# ATSAMRH71F20B register map
Vendor: Microchip Technology; Series: SAMRH71; File version: 0
CPU: CM7 r1p1, little endian, MPU, FPU, 3 interrupt priority bits
Registers are 32-bit, read-write, reset 0x0 unless marked. A register's access mark holds for its fields unless they carry their own. Offsets are from the block's base; [hi:lo] are bit positions; 'fields as' and 'values as' point back to an identical list.

## SUPC — Supply Controller
Base 0x40100210; register names take the prefix SUPC_
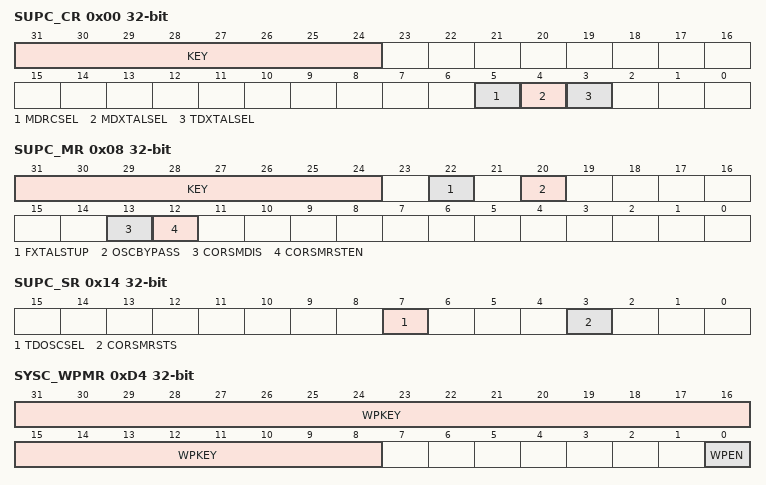
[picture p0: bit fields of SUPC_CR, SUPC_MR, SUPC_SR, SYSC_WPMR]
0x00 SUPC_CR wo — Supply Controller Control Register
  [31:24] KEY — Password
    165=PASSWD (Writing any other value in this field aborts the write operation.)
  [5] MDRCSEL — Monitoring Domain RC Oscillator Select
    0=NO_EFFECT; 1=CRYSTAL_SEL (If KEY is correct, XTALSEL switches the slow clock of the monitoring domain (MD_SLCK) on the slow RC oscillator output.)
  [4] MDXTALSEL — Monitoring Domain Crystal Oscillator Select
    0=NO_EFFECT; 1=CRYSTAL_SEL (If KEY is correct, XTALSEL switches the slow clock of the monitoring domain (MD_SLCK) on the 32.768 kHz crystal oscillator output.)
  [3] TDXTALSEL — Timing Domain Crystal Oscillator Select
    0=NO_EFFECT; 1=CRYSTAL_SEL (If KEY is correct, XTALSEL switches the slow clock of the timing domain (TD_SLCK) on the 32.768 kHz crystal oscillator output.)
0x04 SUPC_SMMR — Supply Controller Supply Monitor Mode Register
  [23] CORESMUSEL — Core Supply Monitor User Selection
0x08 SUPC_MR — Supply Controller Mode Register
  [31:24] KEY — Password Key
    values as SUPC_CR.KEY
  [22] FXTALSTUP — Fast Startup 32.768 kHz Crystal Oscillator
  [20] OSCBYPASS — Oscillator Bypass
    0=NO_EFFECT (No effect. Clock selection depends on the value of XTALSEL (SUPC_CR).); 1=BYPASS (The 32.768 kHz crystal oscillator is bypassed if XTALSEL (SUPC_CR) is set. OSCBYPASS must be set prior to setting XTALSEL.)
  [13] CORSMDIS — VDDCORE Supply Monitor Disable
    0=ENABLE (The VDDCORE supply monitor is enabled.); 1=DISABLE (The VDDCORE supply monitor is disabled.)
  [12] CORSMRSTEN — VDDCORE Supply Monitor Reset Enable
    0=NOT_ENABLE (The core reset signal vddcore_nreset is not affected when a VDDCORE supply monitor detection occurs.); 1=ENABLE (The core reset signal, vddcore_nreset is asserted when a VDDCORE supply monitor detection occurs.)
0x14 SUPC_SR ro — Supply Controller Status Register
  [7] TDOSCSEL — 32 kHz Oscillator Selection Status
    0=RC (The timing domain slow clock, TD_SLCK, is generated by the slow RC oscillator.); 1=CRYST (The timing domain slow clock, TD_SLCK, is generated by the 32.768 kHz crystal oscillator.)
  [3] CORSMRSTS — VDDCORE Supply Monitor Reset Status (cleared on read)
    0=NO (No VDDCORE Supply Monitor reset event has been detected since the last read of the SUPC_SR.); 1=PRESENT (At least one VDDCORE Supply Monitor reset event has been detected since the last read of the SUPC_SR.)
0x1C SUPC_PWR — Supply Controller Power Register
  [18] MONSELS — Monitoring Oscillator Selection Status
    0=RC (The monitoring domain slow clock, MD_SLCK, is generated by the slow RC oscillator.); 1=CRYST (The monitoring domain slow clock, MD_SLCK, is generated by the 32.768 kHz crystal oscillator.)
0xD4 SYSC_WPMR — Write Protection Mode Register
  [31:8] WPKEY — Write Protection Key.
    0x525443=PASSWD (Writing any other value in this field aborts the write operation of the WPEN bit.Always reads as 0.)
  [0] WPEN — Write Protection Enable

## TCMECC — HECC
Base 0x40100400; register names take the prefix TCMECC_
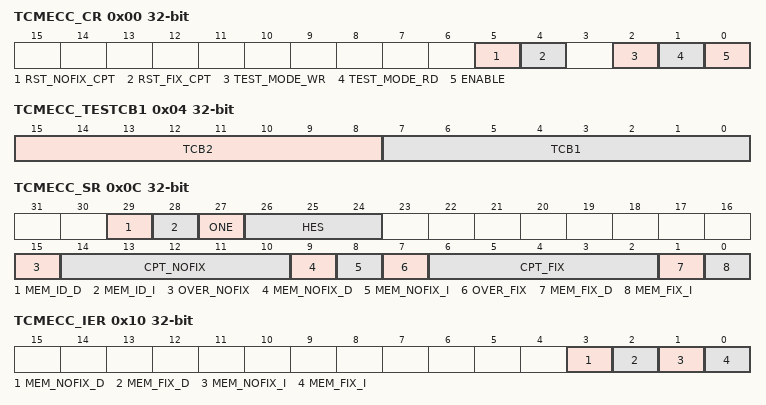
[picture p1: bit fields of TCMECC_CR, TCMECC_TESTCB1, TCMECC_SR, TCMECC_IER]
0x00 TCMECC_CR — TCMECC Control Register
  [5] RST_NOFIX_CPT — reset the un-fixable error counter
  [4] RST_FIX_CPT — reset the fixable error counter
  [2] TEST_MODE_WR — test mode of ECC protection - write mode
  [1] TEST_MODE_RD — test mode of ECC protection - read mode
  [0] ENABLE — ECC protection enable
0x04 TCMECC_TESTCB1 — TCMECC Test mode register 1
  [15:8] TCB2 — test check bit (8 bit)
  [7:0] TCB1 — test check bit (8 bit)
0x0C TCMECC_SR ro — TCMECC Status register
  [29] MEM_ID_D — memory identification number
  [28] MEM_ID_I — memory identification number
  [27] ONE
  [26:24] HES — Hardware Error Size
  [15] OVER_NOFIX — counter overflow
  [14:10] CPT_NOFIX — 5 bits counter
  [9] MEM_NOFIX_D — Un-fixable error status in data memory
  [8] MEM_NOFIX_I — Un-fixable error status in instruction memory
  [7] OVER_FIX — counter overflow
  [6:2] CPT_FIX — 5 bits counter
  [1] MEM_FIX_D — Fixable error status in data memory
  [0] MEM_FIX_I — Fixable error status in instruction memory
0x10 TCMECC_IER wo — TCMECC Interrupt Enable Register
  [3] MEM_NOFIX_D — Un-fixable error on data
  [2] MEM_FIX_D — Fixable error on data
  [1] MEM_NOFIX_I — Un-fixable error on instruction
  [0] MEM_FIX_I — Fixable error on instruction
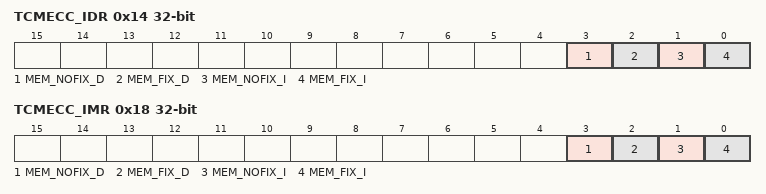
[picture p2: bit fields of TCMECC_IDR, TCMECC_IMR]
0x14 TCMECC_IDR wo — TCMECC Interrupt Disable Register
  [3] MEM_NOFIX_D — un-fixable error on data
  [2] MEM_FIX_D — fixable error on data
  [1] MEM_NOFIX_I — un-fixable error on instruction
  [0] MEM_FIX_I — fixable error on instruction
0x18 TCMECC_IMR ro — TCMECC Interrupt Mask Register
  fields as TCMECC_IDR
0x1C TCMECC_FAILAR ro — TCMECC Fail address register
  [31:0] ADDRESS — address of the error detected (refers to instruction memory)
0x20 TCMECC_FAILARD ro — TCMECC Fail address register data
  [31:0] ADDRESS — address of the error detected
